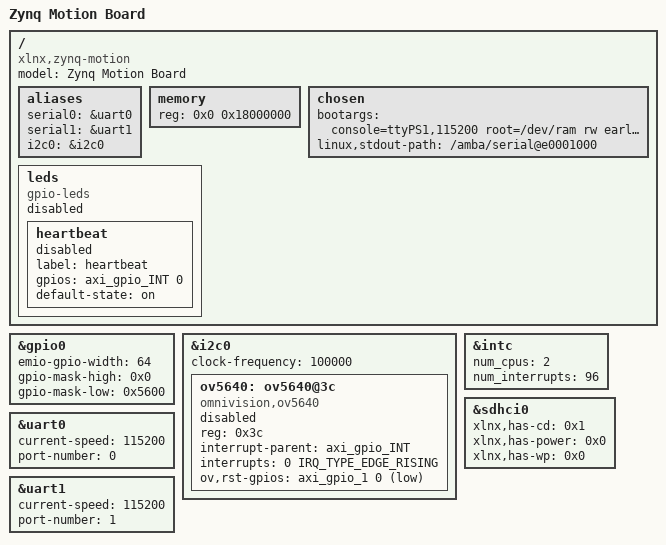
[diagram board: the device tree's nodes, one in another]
/*
 *  Copyright (C) 2011 - 2014 Xilinx
 *  Copyright (C) 2012 National Instruments Corp.
 *
 * This software is licensed under the terms of the GNU General Public
 * License version 2, as published by the Free Software Foundation, and
 * may be copied, distributed, and modified under those terms.
 *
 * This program is distributed in the hope that it will be useful,
 * but WITHOUT ANY WARRANTY; without even the implied warranty of
 * MERCHANTABILITY or FITNESS FOR A PARTICULAR PURPOSE.  See the
 * GNU General Public License for more details.
 *
 * 修改记录
 * 日期         修改人          描述
 * 20160306     刘旭升          feat: 支持zynq-motion项目
 */
/dts-v1/;
#include <dt-bindings/gpio/gpio.h>
#include <dt-bindings/interrupt-controller/irq.h>
/include/ "zynq-7000.dtsi"
/include/ "zynq-motion-pl.dtsi"

/ {
	model = "Zynq Motion Board";
	compatible = "xlnx,zynq-motion", "xlnx,zynq-7000";

	aliases {
		serial0 = &uart0;
        serial1 = &uart1;
        i2c0 = &i2c0;
	};

	memory {
		device_type = "memory";
		reg = <0x0 0x18000000>;
	};

	chosen {
		bootargs = "console=ttyPS1,115200 root=/dev/ram rw earlyprintk mem=384M printk.time=1";
		linux,stdout-path = "/amba/serial@e0001000";
	};

    leds {
        compatible = "gpio-leds";
        status = "disabled";

        heartbeat {
            label = "heartbeat";
            gpios = <&axi_gpio_INT 0 0>;
            default-state = "on";
            status = "disabled";
        };
    };
};

&gpio0 {
	emio-gpio-width = <64>;
	gpio-mask-high = <0x0>;
	gpio-mask-low = <0x5600>;
};

&i2c0 {
	clock-frequency = <100000>;
	status = "okay";

    ov5640: ov5640@3c {
        compatible = "omnivision,ov5640";
        reg = <0x3c>;
        interrupt-parent = <&axi_gpio_INT>;
        interrupts = <0 IRQ_TYPE_EDGE_RISING>;
        ov,rst-gpios = <&axi_gpio_1 0 GPIO_ACTIVE_LOW>;
        /*ov,irq-gpio = <&axi_gpio_INT 0 GPIO_ACTIVE_HIGH>;*/
        status = "disabled";
    };
};

&intc {
	num_cpus = <2>;
	num_interrupts = <96>;
};

&sdhci0 {
    xlnx,has-cd = <0x1>;
    xlnx,has-power = <0x0>;
    xlnx,has-wp = <0x0>;
	status = "okay";
};

&uart0 {
	current-speed = <115200>;
	device_type = "serial";
	port-number = <0>;
	status = "okay";
};

&uart1 {
    current-speed = <115200>;
	device_type = "serial";
	port-number = <1>;
	status = "okay";
};
